# pse84_a0 register map
Vendor: Infineon Technologies; Series: PSE84_A0; File version: 1.0
CPU: CM33 r0p1, little endian, MPU, FPU, VTOR, 3 interrupt priority bits
Registers are 32-bit, read-write, reset 0x0 unless marked. A register's access mark holds for its fields unless they carry their own. Offsets are from the block's base; [hi:lo] are bit positions; lines under a group give offsets from that group; {n}, {i} and the like mark numbered series; 'fields as' and 'values as' point back to an identical list.

## CTBL0 — Continuous Time Block Lite
Base 0x42E00000
Same registers: CTBL1 0x42E10000
0x400 STA group — CTBL static configuration
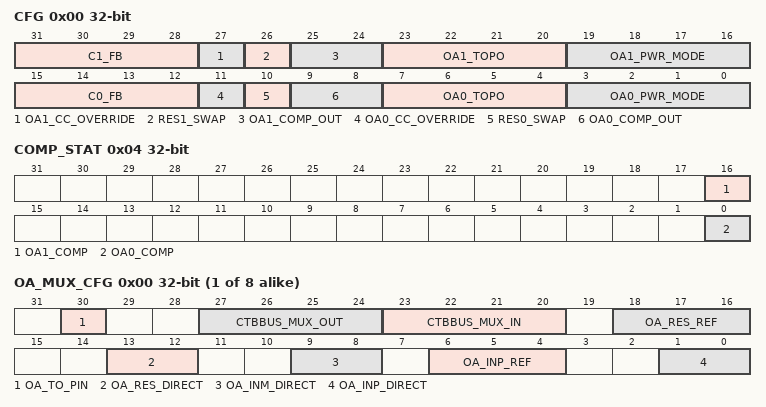
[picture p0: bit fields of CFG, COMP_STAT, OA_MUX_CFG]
  0x00 CFG — Configuration (only accessible if ACTRLR.STATUS.MODE=0)
    [31:28] C1_FB — Feed back Cap value (see C0_FB)
    [27] OA1_CC_OVERRIDE — Opamp1 compensation capacitor override (see OA0_CC_OVERRIDE)
      0=DISABLE (N/A); 1=ENABLE (N/A)
    [26] RES1_SWAP — Swap Top and Bottom resistor value (see RES0_SWAP)
    [25:24] OA1_COMP_OUT — Opamp1 comparator edge detect output (for interrupt and trigger generation)
      0=DISABLE (Disabled, no interrupts will be detected); 1=RISING (Rising edge); 2=FALLING (Falling edge); 3=BOTH (Both rising and falling edges)
    [23:20] OA1_TOPO — OA1 Opamp Configuration: see description of OA0_CFG
    [19:16] OA1_PWR_MODE — Opamp1 power level: see description of OA0_PWR_MODE
    [15:12] C0_FB — Feed back Cap value select This field is only used if OA0_TOPO is set to 1, 2, or 4 and the Opamp Gain (set by the AC) is set to a non-unity value. The feedback capacitor is used to compensate the resistive feedback network. Values range from 0pF to 10.5pF in 0.7pF increments. 0000: 0pF 0001: 0.7pF 0010: 1.4pF 0011: 2.1pF 0100: 2.8pF 0101: 3.5pF 0110: 4.2pF 0111: 4.9pF 1000: 5.6pF 1001: 6.3pF 1010: 7.0pF 1011: 7.7pF 1100: 8.4pF 1101: 9.1pF 1110: 9.8pF 1111: 10.5pF
    [11] OA0_CC_OVERRIDE — Opamp0 miller compensation capacitor override
      0=DISABLE (The compensation capacitor value is determined by CTBL_TRIM_STRUCT.OA0_COMP_TRIM.OA0_COMP_TRIM); 1=ENABLE (Opamp0 contains no miller compensation capactior.)
    [10] RES0_SWAP
    [9:8] OA0_COMP_OUT — 6= Buffer
      values as OA1_COMP_OUT
    [7:4] OA0_TOPO
    [3:0] OA0_PWR_MODE — Opamp0 power level
      0=OFF; 1=ULTRA_LOW (If CTBL_DYN_CFG_STRUCT.OA_MUX_CFG.OA_TO_PIN=0: opamp quiscent current of 15uA, input common mode of 0.2V to VDDA-1V, gain bandwidth of 30kHz. If CTBL_DYN_CFG_STRUCT.OA_MUX_CFG.OA_TO_PIN=1: opamp quiscent current of 15uA, input common mode of 0.2V to VDDA-1V, gain bandwidth of 100kHz, 10uA output drive capability.); 2=ULTRA_LOW_RAIL (If CTBL_DYN_CFG_STRUCT.OA_MUX_CFG.OA_TO_PIN=0: opamp quiscent current of 35uA, input common mode of 0.2V to VDDA-0.2V, gain bandwidth of 30kHz. If CTBL_DYN_CFG_STRUCT.OA_MUX_CFG.OA_TO_PIN=1: opamp quiscent current of 35uA, input common mode of 0.2V to VDDA-0.2V, gain bandwidth of 100kHz, 10uA output drive capability.); 3=LOW (Do Not Use); 4=LOW_RAIL (If CTBL_DYN_CFG_STRUCT.OA_MUX_CFG.OA_TO_PIN=0: opamp quiscent current of 150uA, input common mode of 0.2V to VDDA-0.2V, gain bandwidth of 350kHz. If CTBL_DYN_CFG_STRUCT.OA_MUX_CFG.OA_TO_PIN=1: opamp quiscent current of 150uA, input common mode of 0.2V to VDDA-0.2V, gain bandwidth of 1.2MHz, 100uA output drive capability.); 5=MEDIUM (Do Not Use); 6=MEDIUM_RAIL (If CTBL_DYN_CFG_STRUCT.OA_MUX_CFG.OA_TO_PIN=0: opamp quiscent current of 200uA, input common mode of 0.2V to VDDA-0.2V, gain bandwidth of 700kHz. If CTBL_DYN_CFG_STRUCT.OA_MUX_CFG.OA_TO_PIN=1: opamp quiscent current of 200uA, input common mode of 0.2V to VDDA-0.2V, gain bandwidth of 2.4MHz, 1mA output drive capability.); 7=HIGH (Do Not Use); 8=HIGH_RAIL (If CTBL_DYN_CFG_STRUCT.OA_MUX_CFG.OA_TO_PIN=0: opamp quiscent current of 600uA, input common mode of 0.2V to VDDA-0.2V, gain bandwidth of 1.75MHz. If CTBL_DYN_CFG_STRUCT.OA_MUX_CFG.OA_TO_PIN=1: opamp quiscent current of 600uA, input common mode of 0.2V to VDDA-0.2V, gain bandwidth of 6MHz,1mA output drive capability.); 9=ULTRA_HIGH (Do Not Use); 10=ULTRA_HIGH_RAIL (If CTBL_DYN_CFG_STRUCT.OA_MUX_CFG.OA_TO_PIN=0: opamp quiscent current of 800uA, input common mode of 0.2V to VDDA-0.2V, gain bandwidth of 2.8MHz. If CTBL_DYN_CFG_STRUCT.OA_MUX_CFG.OA_TO_PIN=1: opamp quiscent current of 800uA, input common mode of 0.2V to VDDA-0.2V, gain bandwidth of 7.5MHz, 10mA output drive capability.); {v}=RSVD_{v-11} (N/A) (v=11..15)
  0x04 COMP_STAT ro — Comparator status
    [16] OA1_COMP — Opamp1 current comparator status
    [0] OA0_COMP — Opamp0 current comparator status
{0x600+0x10*i} DYN[{i}] (i=0..7) group — CTBL dynamic configuration structure (only accessible if ACTRLR.STATUS.MODE=0)
  0x00 OA_MUX_CFG — Opamp Mux Configuration
    [30] OA_TO_PIN — OA Output connects to pin
    [27:24] CTBBUS_MUX_OUT
    [23:20] CTBBUS_MUX_IN
    [18:16] OA_RES_REF
    [13:12] OA_RES_DIRECT
    [9:8] OA_INM_DIRECT — Opamp inverting terminal direct connection 0 = Disconnected 1 = OA0: P0 OA1: P5 2 = OA0: P1 OA1: P4 3 = OA0: BJT Base (using P0) OA1: BJT Base (using P5)
    [6:4] OA_INP_REF — Opamp non-inverting terminal reference connection 0 = Disconnected 1 = vref0 2 = vref1 3 = vref2 4 = vref3 5 = vbgr 6 = Adjacent CTBL OA0 Output 7 = Adjacent CTBL OA1 Output
    [1:0] OA_INP_DIRECT
0xF00 TRIM group — CTBL trim structure (only accessible if ACTRLR.STATUS.MODE=0)
  0x00 OA0_OFFSET_TRIM — Opamp0 trim control
    [5:0] OA0_OFFSET_TRIM — Opamp0 offset trim
  0x04 OA0_SLOPE_OFFSET_TRIM — Opamp0 trim control
    [5:0] OA0_SLOPE_OFFSET_TRIM — Opamp0 slope offset drift trim
  0x08 OA0_COMP_TRIM — Opamp0 trim control
    [3:0] OA0_COMP_TRIM — Opamp0 Compensation Capacitor Trim Bit<3> is not used Bits<2:0> 000 = 0.1pF 001 = 1.1pF 010 = 2.1pF 011 = 3.1pF 100 = 4.1pF 101 = 5.1pF 110 = 6.1pF 111 = 7.1pF
  0x0C OA1_OFFSET_TRIM — Opamp1 trim control
    [5:0] OA1_OFFSET_TRIM — Opamp1 offset trim
  0x10 OA1_SLOPE_OFFSET_TRIM — Opamp1 trim control
    [5:0] OA1_SLOPE_OFFSET_TRIM — Opamp1 slope offset drift trim
  0x14 OA1_COMP_TRIM — Opamp1 trim control
    [3:0] OA1_COMP_TRIM — Opamp1 Compensation Capacitor Trim (See OA0_COMP_TRIM)
  0x18 RMP_TRIM reset 0x1 — Risk Mitigation bits
    [3:0] RMP_TRIM
